BO_ 1541 TP_Dashboard: 6 Dashboard
 SG_ data : 0|48@1+ (1,0) [0|0] ""  Console

BO_ 1792 Diag_Request: 8 Vector__XXX

BO_ 1536 Diag_Response: 8 Vector__XXX

BO_ 1537 DiagResponse_Motor: 8 Gateway
 SG_ data : 0|64@1+ (1,0) [0|0] "" Vector__XXX

BO_ 1543 DiagResponse_DoorLeft: 8 DOOR_le
 SG_ data : 0|64@1+ (1,0) [0|0] "" Vector__XXX

BO_ 1542 DiagRequest: 8 Vector__XXX
 SG_ data : 0|64@1+ (1,0) [0|0] ""  DOOR_le

BO_ 1540 TP_Console: 6 Console
 SG_ data : 0|48@1+ (1,0) [0|0] ""  Dashboard

BO_ 1053 NM_Gateway: 4 Gateway
 SG_ SleepInd : 12|1@1+ (1,0) [0|0] ""  Gateway,DOOR_ri,DOOR_le

BO_ 1052 NM_DOORright: 4 DOOR_ri
 SG_ SleepInd : 12|1@1+ (1,0) [0|0] ""  Gateway,DOOR_le

BO_ 1051 NM_DOORleft: 4 DOOR_le
 SG_ SleepInd : 12|1@1+ (1,0) [0|0] ""  Gateway,DOOR_ri

BO_ 1050 NM_Console: 4 Console
 SG_ SleepInd : 12|1@1+ (1,0) [0|0] ""  Console,Gateway,DOOR_ri,DOOR_le

BO_ 497 DOOR_r: 1 DOOR_ri
 SG_ WN_Position : 0|8@1+ (1,0) [0|100] "" Vector__XXX

BO_ 496 DOOR_l: 1 DOOR_le
 SG_ WN_Position : 0|8@1+ (1,0) [0|100] "" Vector__XXX

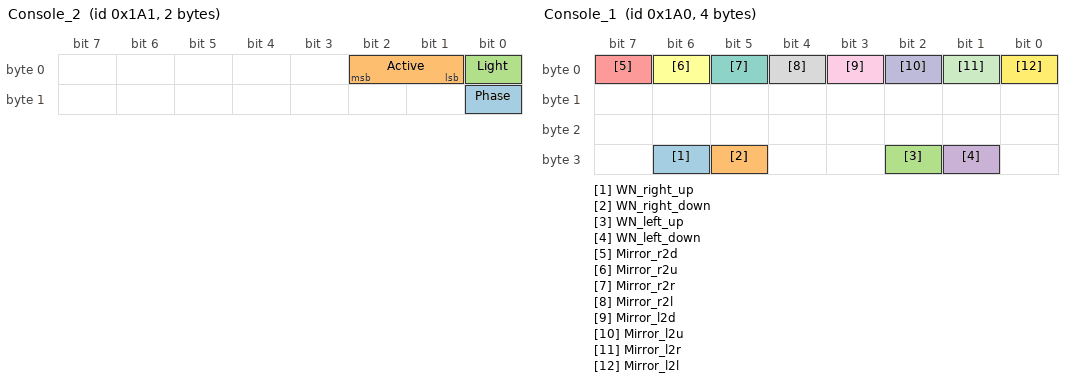
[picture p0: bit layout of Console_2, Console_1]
BO_ 417 Console_2: 2 Console
 SG_ Phase : 8|1@1+ (1,0) [0|0] "" Vector__XXX
 SG_ Active : 1|2@1+ (1,0) [0|0] "" Vector__XXX
 SG_ Light : 0|1@1+ (1,0) [0|1] "" Vector__XXX

BO_ 416 Console_1: 4 Console
 SG_ WN_right_up : 30|1@1+ (1,0) [0|0] ""  DOOR_ri
 SG_ WN_right_down : 29|1@1+ (1,0) [0|0] ""  DOOR_ri
 SG_ WN_left_up : 26|1@1+ (1,0) [0|0] ""  DOOR_le
 SG_ WN_left_down : 25|1@1+ (1,0) [0|0] ""  DOOR_le
 SG_ Mirror_r2d : 7|1@1+ (1,0) [0|0] "" Vector__XXX
 SG_ Mirror_r2u : 6|1@1+ (1,0) [0|0] "" Vector__XXX
 SG_ Mirror_r2r : 5|1@1+ (1,0) [0|0] "" Vector__XXX
 SG_ Mirror_r2l : 4|1@1+ (1,0) [0|0] "" Vector__XXX
 SG_ Mirror_l2d : 3|1@1+ (1,0) [0|0] "" Vector__XXX
 SG_ Mirror_l2u : 2|1@1+ (1,0) [0|0] "" Vector__XXX
 SG_ Mirror_l2r : 1|1@1+ (1,0) [0|0] "" Vector__XXX
 SG_ Mirror_l2l : 0|1@1+ (1,0) [0|0] "" Vector__XXX

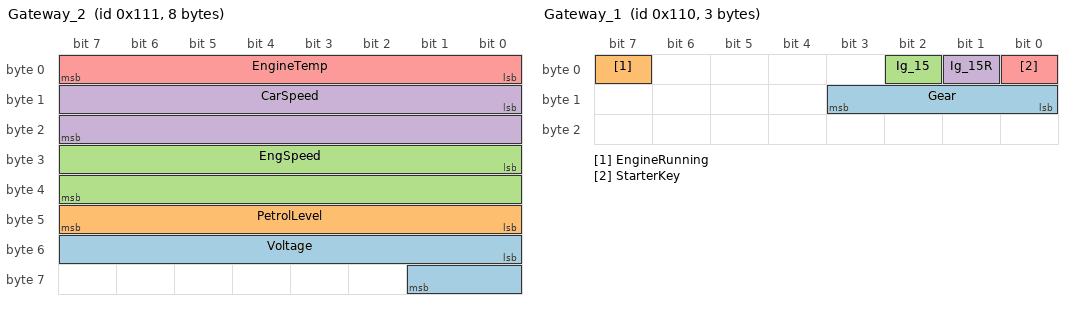
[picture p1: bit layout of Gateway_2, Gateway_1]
BO_ 273 Gateway_2: 8 Gateway
 SG_ Voltage : 48|10@1+ (0.1,0) [0|102.3] "V" Vector__XXX
 SG_ PetrolLevel : 40|8@1+ (1,0) [0|0] ""  Dashboard
 SG_ EngSpeed : 24|16@1+ (1,0) [0|0] ""  Dashboard
 SG_ CarSpeed : 8|16@1+ (0.5,0) [0|300] ""  Dashboard
 SG_ EngineTemp : 0|8@1+ (1,0) [0|0] ""  Dashboard

BO_ 272 Gateway_1: 3 Gateway
 SG_ Gear : 8|4@1- (1,0) [0|0] ""  Dashboard
 SG_ EngineRunning : 7|1@1+ (1,0) [0|0] "" Vector__XXX
 SG_ Ig_15 : 2|1@1+ (1,0) [0|0] ""  Dashboard,Console
 SG_ Ig_15R : 1|1@1+ (1,0) [0|0] ""  Dashboard
 SG_ StarterKey : 0|1@1+ (1,0) [0|1] ""  Dashboard

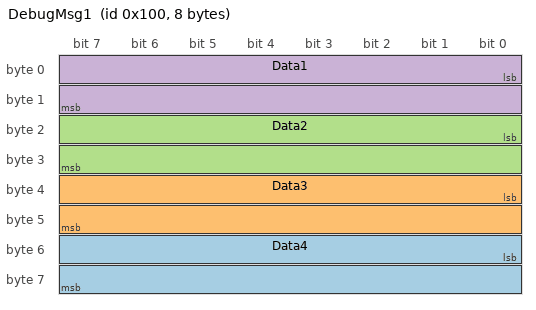
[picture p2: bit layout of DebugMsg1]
BO_ 256 DebugMsg1: 8 Vector__XXX
 SG_ Data4 : 48|16@1- (1,0) [0|0] ""  Gateway
 SG_ Data3 : 32|16@1- (1,0) [0|0] ""  Gateway
 SG_ Data2 : 16|16@1- (1,0) [0|0] ""  Gateway
 SG_ Data1 : 0|16@1- (1,0) [0|0] ""  Gateway
